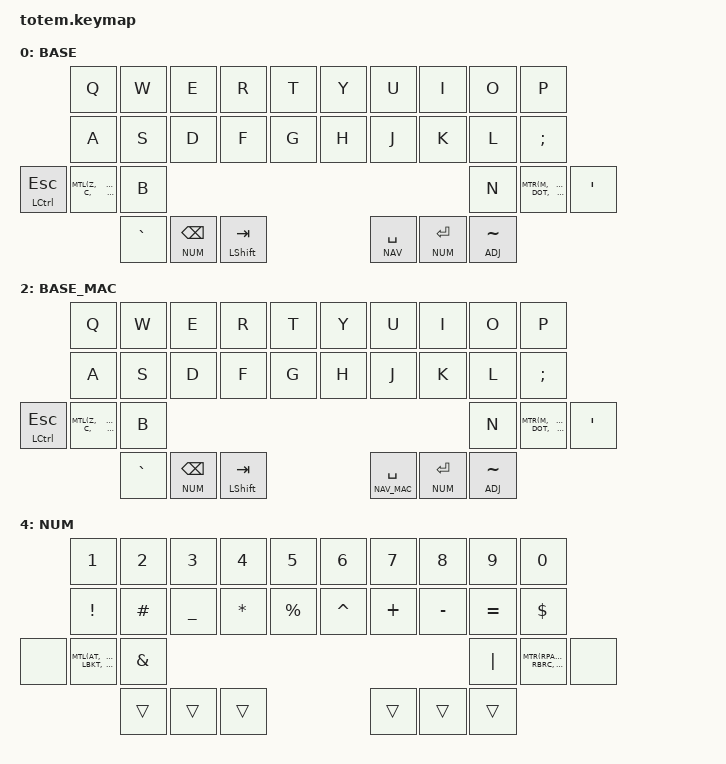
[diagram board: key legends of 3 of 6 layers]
//
//                                                        ▀▀▀▀▀     ▀▀▀▀▀          ▀▀█▀▀
//                                                        ▄▀▀▀▄  ▄  ▄▀▀▀▄  ▄  ▄▀▀▀▄  █  ▄▀▀▀▄
//                                                        █   █  █  █   █  █  █   █  █  █   █
//                                                         ▀▀▀   █   ▀▀▀   █   ▀▀▀   ▀   ▀▀▀
//                                                               █      ▄▄▄█▄▄▄    █   █  
//                                                               ▀      █  █  █     █▄█
//                                                             ▀▀▀▀▀    █  █  █      ▀
//                                                                      ▀  ▀  ▀
//
// ▄▄▄▄▄▄▄▄▄▄▄▄▄▄▄▄▄▄▄▄▄▄▄▄▄▄▄▄▄▄▄▄▄▄▄▄▄▄▄▄▄▄▄▄▄▄▄▄▄▄▄▄▄▄▄▄▄▄▄▄▄▄▄▄▄▄▄▄▄▄▄▄▄▄▄▄▄▄▄▄▄▄▄▄▄▄▄▄▄▄▄▄▄▄▄▄▄▄▄▄▄▄▄▄▄▄▄▄▄▄▄▄▄▄▄▄▄▄▄▄▄▄▄▄▄▄▄▄▄▄▄▄▄▄▄▄▄▄▄▄▄▄▄▄▄▄▄▄▄
       

#include <behaviors.dtsi>
#include <dt-bindings/zmk/keys.h>
#include <dt-bindings/zmk/bt.h>
#include <dt-bindings/zmk/outputs.h>

#define MTL(k1, k2, k3, k4) &mtl LGUI k1 &mtl LALT k2 &mtl LSHFT k3 &mtl LCTRL k4
#define MTR(k1, k2, k3, k4) &mtr RCTRL k1 &mtr RSHFT k2 &mtr RALT k3 &mtr RGUI k4

#define BASE      0
#define NAV       1
#define BASE_MAC  2
#define NAV_MAC   3
#define NUM       4
#define ADJ       5


// |------------------------|------------------------|
// | LEFT_HAND_KEYS         |        RIGHT_HAND_KEYS |
// |                        |                        |
// |     0  1  2  3  4      |       5  6  7  8  9    |
// |    10 11 12 13 14      |      15 16 17 18 19    |
// | 20 21 22 23 24 25      |      26 27 28 29 30 31 |
// |          32 33 34      |      35 36 37          |
// |------------------------|------------------------| 

/ {
    combos {
        compatible = "zmk,combos";
        combo_esc {
            timeout-ms = <35>;
            key-positions = <16 17>;
            bindings = <&kp ESC>;
        };
    };

    behaviors {
        mtt: mod_tap_thumbs {
            compatible = "zmk,behavior-hold-tap";
            #binding-cells = <2>;
            flavor = "balanced";
            tapping-term-ms = <180>;
            bindings = <&kp>, <&kp>;
            retro-tap;
            
        };
        mtl: mod_tap_left {
            compatible = "zmk,behavior-hold-tap";
            #binding-cells = <2>;
            flavor = "balanced";
            require-prior-idle-ms = <110>;
            tapping-term-ms = <215>;
            quick-tap-ms = <175>;
            bindings = <&kp>, <&kp>;
            hold-trigger-key-positions = <5 6 7 8 9 15 16 17 18 19 26 27 28 29 30 31 32 33 34 35 36 37>;
            hold-trigger-on-release;
        };
        mtr: mod_tap_right {
            compatible = "zmk,behavior-hold-tap";
            #binding-cells = <2>;
            flavor = "balanced";
            require-prior-idle-ms = <110>;
            tapping-term-ms = <215>;
            quick-tap-ms = <175>;
            bindings = <&kp>, <&kp>;
            hold-trigger-key-positions = <0 1 2 3 4 10 11 12 13 14 20 21 22 23 24 25 32 33 34 35 36 37>;
            hold-trigger-on-release;
        };
    };

    keymap {
            compatible = "zmk,keymap";
// ▄▄▄▄▄▄▄▄▄▄▄▄▄▄▄▄▄▄▄▄▄▄▄▄▄▄▄▄▄▄▄▄▄▄▄▄▄▄▄▄▄▄▄▄▄▄▄▄▄▄▄▄▄▄▄▄▄▄▄▄▄▄▄▄▄▄▄▄▄▄▄▄▄▄▄▄▄▄▄▄▄▄▄▄▄▄▄▄▄▄▄▄▄▄▄▄▄▄▄▄▄▄▄▄▄▄▄▄▄▄▄▄▄▄▄▄▄▄▄▄▄▄▄▄▄▄▄▄▄▄▄▄▄▄▄▄▄▄▄▄▄▄▄▄▄▄▄▄▄

                base_layer {
// ┏━━━━━━━━━━━━━━━━━━━━━━━━━━━━━━━━━━━━━━━┓
label= "BASE"                              ;
// ┗━━━━━━━━━━━━━━━━━━━━━━━━━━━━━━━━━━━━━━━┛
//             ┏━━━━━━━━━━━┳━━━━━━━━━━━┳━━━━━━━━━━━┳━━━━━━━━━━━┳━━━━━━━━━━━┓   ┏━━━━━━━━━━━┳━━━━━━━━━━━┳━━━━━━━━━━━┳━━━━━━━━━━━┳━━━━━━━━━━━┓
//             ┃     Q     ┃     W     ┃     E     ┃     R     ┃     T     ┃   ┃     Y     ┃     U     ┃     I     ┃     O     ┃     P     ┃
//             ┣━━━━━━━━━━━╋━━━━━━━━━━━╋━━━━━━━━━━━╋━━━━━━━━━━━╋━━━━━━━━━━━┫   ┣━━━━━━━━━━━╋━━━━━━━━━━━╋━━━━━━━━━━━╋━━━━━━━━━━━╋━━━━━━━━━━━┫
//             ┃     A     ┃     S     ┃     D     ┃     F     ┃     G     ┃   ┃     H     ┃     J     ┃     K     ┃     L     ┃     ;     ┃
// ┏━━━━━━━━━━━╋━━━━━━━━━━━╋━━━━━━━━━━━╋━━━━━━━━━━━╋━━━━━━━━━━━╋━━━━━━━━━━━┫   ┣━━━━━━━━━━━╋━━━━━━━━━━━╋━━━━━━━━━━━╋━━━━━━━━━━━╋━━━━━━━━━━━╋━━━━━━━━━━━┓
// ┃    ESC    ┃     Z     ┃     X     ┃     C     ┃     V     ┃     B     ┃   ┃     N     ┃     M     ┃     ,     ┃     .     ┃     /     ┃     '     ┃
// ┗━━━━━━━━━━━┻━━━━━━━━━━━┻━━━━━━━━━━━╋━━━━━━━━━━━╋━━━━━━━━━━━╋━━━━━━━━━━━┫   ┣━━━━━━━━━━━╋━━━━━━━━━━━╋━━━━━━━━━━━╋━━━━━━━━━━━┻━━━━━━━━━━━┻━━━━━━━━━━━┛
//                                     ┃           ┃    BSPC   ┃    TAB    ┃   ┃   SPACE   ┃   ENTER   ┃    ADJ    ┃
//                                     ┗━━━━━━━━━━━┻━━━━━━━━━━━┻━━━━━━━━━━━┛   ┗━━━━━━━━━━━┻━━━━━━━━━━━┻━━━━━━━━━━━┛
 bindings = <
// ╷           ╷           ╷           ╷           ╷           ╷           ╷   ╷           ╷           ╷           ╷           ╷           ╷           ╷

                &kp Q       &kp W       &kp E       &kp R       &kp T           &kp Y       &kp U       &kp I       &kp O       &kp P
                &kp A       &kp S       &kp D       &kp F       &kp G           &kp H       &kp J       &kp K       &kp L       &kp SEMI
 &mtt LCTRL ESC MTL(Z,          X,          C,          V)      &kp B           &kp N       MTR(M,          COMMA,      DOT,        FSLH)    &kp SQT
                            &kp GRAVE   &lt NUM BSPC &mtt LSHFT TAB             &lt NAV SPACE   &lt NUM ENTER   &lt ADJ TILDE
                        >;
                };

// ▄▄▄▄▄▄▄▄▄▄▄▄▄▄▄▄▄▄▄▄▄▄▄▄▄▄▄▄▄▄▄▄▄▄▄▄▄▄▄▄▄▄▄▄▄▄▄▄▄▄▄▄▄▄▄▄▄▄▄▄▄▄▄▄▄▄▄▄▄▄▄▄▄▄▄▄▄▄▄▄▄▄▄▄▄▄▄▄▄▄▄▄▄▄▄▄▄▄▄▄▄▄▄▄▄▄▄▄▄▄▄▄▄▄▄▄▄▄▄▄▄▄▄▄▄▄▄▄▄▄▄▄▄▄▄▄▄▄▄▄▄▄▄▄▄▄▄▄▄


                nav_layer {
// ┏━━━━━━━━━━━━━━━━━━━━━━━━━━━━━━━━━━━━━━━┓
label= "NAVI"                              ;
// ┗━━━━━━━━━━━━━━━━━━━━━━━━━━━━━━━━━━━━━━━┛
//             ┏━━━━━━━━━━━┳━━━━━━━━━━━┳━━━━━━━━━━━┳━━━━━━━━━━━┳━━━━━━━━━━━┓   ┏━━━━━━━━━━━┳━━━━━━━━━━━┳━━━━━━━━━━━┳━━━━━━━━━━━┳━━━━━━━━━━━┓
//             ┃           ┃           ┃CTRL(RIGHT)┃           ┃           ┃   ┃ CTRL(INS) ┃   PG_UP   ┃    HOME   ┃           ┃  SFT(INS) ┃
//             ┣━━━━━━━━━━━╋━━━━━━━━━━━╋━━━━━━━━━━━╋━━━━━━━━━━━╋━━━━━━━━━━━┫   ┣━━━━━━━━━━━╋━━━━━━━━━━━╋━━━━━━━━━━━╋━━━━━━━━━━━╋━━━━━━━━━━━┫
//             ┃    END    ┃    SS     ┃   PG_DN   ┃           ┃           ┃   ┃   LEFT    ┃    DOWN   ┃     UP    ┃   RIGHT   ┃    DEL    ┃
// ┏━━━━━━━━━━━╋━━━━━━━━━━━╋━━━━━━━━━━━╋━━━━━━━━━━━╋━━━━━━━━━━━╋━━━━━━━━━━━┫   ┣━━━━━━━━━━━╋━━━━━━━━━━━╋━━━━━━━━━━━╋━━━━━━━━━━━╋━━━━━━━━━━━╋━━━━━━━━━━━┓
// ┃   CAPS    ┃   K_PP    ┃   K_PREV  ┃  K_NEXT   ┃           ┃ CTRL(LEFT)┃   ┃           ┃           ┃           ┃           ┃           ┃           ┃
// ┗━━━━━━━━━━━┻━━━━━━━━━━━┻━━━━━━━━━━━╋━━━━━━━━━━━╋━━━━━━━━━━━╋━━━━━━━━━━━┫   ┣━━━━━━━━━━━╋━━━━━━━━━━━╋━━━━━━━━━━━╋━━━━━━━━━━━┻━━━━━━━━━━━┻━━━━━━━━━━━┛
//                                     ┃           ┃           ┃           ┃   ┃           ┃           ┃           ┃
//                                     ┗━━━━━━━━━━━┻━━━━━━━━━━━┻━━━━━━━━━━━┛   ┗━━━━━━━━━━━┻━━━━━━━━━━━┻━━━━━━━━━━━┛
 bindings = <
// ╷           ╷           ╷           ╷           ╷           ╷           ╷   ╷           ╷           ╷           ╷           ╷           ╷           ╷

                &none       &none     &kp LC(RIGHT) &none       &none           &kp LC(INS) &kp PG_UP   &kp HOME    &none       &kp LS(INS)
                &kp END  &kp LA(LS(S))  &kp PG_DN   &none       &none           &kp LEFT    &kp DOWN    &kp UP      &kp RIGHT   &kp DEL
    &kp CAPS    MTL(K_PP,   K_PREV,     K_NEXT,     GRAVE)      &kp LC(LEFT)    &none       &sk RCTRL   &sk RSHFT   &sk RALT    &sk RGUI   &none      
                                        &trans      &trans      &trans          &trans      &trans      &trans      
                        >;
                };

// // ▄▄▄▄▄▄▄▄▄▄▄▄▄▄▄▄▄▄▄▄▄▄▄▄▄▄▄▄▄▄▄▄▄▄▄▄▄▄▄▄▄▄▄▄▄▄▄▄▄▄▄▄▄▄▄▄▄▄▄▄▄▄▄▄▄▄▄▄▄▄▄▄▄▄▄▄▄▄▄▄▄▄▄▄▄▄▄▄▄▄▄▄▄▄▄▄▄▄▄▄▄▄▄▄▄▄▄▄▄▄▄▄▄▄▄▄▄▄▄▄▄▄▄▄▄▄▄▄▄▄▄▄▄▄▄▄▄▄▄▄▄▄▄▄▄▄▄▄▄


                base_mac_layer {
// ┏━━━━━━━━━━━━━━━━━━━━━━━━━━━━━━━━━━━━━━━┓
label= "BASE_MAC"                          ;
// ┗━━━━━━━━━━━━━━━━━━━━━━━━━━━━━━━━━━━━━━━┛
//             ┏━━━━━━━━━━━┳━━━━━━━━━━━┳━━━━━━━━━━━┳━━━━━━━━━━━┳━━━━━━━━━━━┓   ┏━━━━━━━━━━━┳━━━━━━━━━━━┳━━━━━━━━━━━┳━━━━━━━━━━━┳━━━━━━━━━━━┓
//             ┃     Q     ┃     W     ┃     E     ┃     R     ┃     T     ┃   ┃     Y     ┃     U     ┃     I     ┃     O     ┃     P     ┃
//             ┣━━━━━━━━━━━╋━━━━━━━━━━━╋━━━━━━━━━━━╋━━━━━━━━━━━╋━━━━━━━━━━━┫   ┣━━━━━━━━━━━╋━━━━━━━━━━━╋━━━━━━━━━━━╋━━━━━━━━━━━╋━━━━━━━━━━━┫
//             ┃     A     ┃     S     ┃     D     ┃     F     ┃     G     ┃   ┃     H     ┃     J     ┃     K     ┃     L     ┃     ;     ┃
// ┏━━━━━━━━━━━╋━━━━━━━━━━━╋━━━━━━━━━━━╋━━━━━━━━━━━╋━━━━━━━━━━━╋━━━━━━━━━━━┫   ┣━━━━━━━━━━━╋━━━━━━━━━━━╋━━━━━━━━━━━╋━━━━━━━━━━━╋━━━━━━━━━━━╋━━━━━━━━━━━┓
// ┃    ESC    ┃     Z     ┃     X     ┃     C     ┃     V     ┃     B     ┃   ┃     N     ┃     M     ┃     ,     ┃     .     ┃     /     ┃     '     ┃
// ┗━━━━━━━━━━━┻━━━━━━━━━━━┻━━━━━━━━━━━╋━━━━━━━━━━━╋━━━━━━━━━━━╋━━━━━━━━━━━┫   ┣━━━━━━━━━━━╋━━━━━━━━━━━╋━━━━━━━━━━━╋━━━━━━━━━━━┻━━━━━━━━━━━┻━━━━━━━━━━━┛
//                                     ┃           ┃    BSPC   ┃    TAB    ┃   ┃   SPACE   ┃   ENTER   ┃    ADJ    ┃
//                                     ┗━━━━━━━━━━━┻━━━━━━━━━━━┻━━━━━━━━━━━┛   ┗━━━━━━━━━━━┻━━━━━━━━━━━┻━━━━━━━━━━━┛
 bindings = <
// ╷           ╷           ╷           ╷           ╷           ╷           ╷   ╷           ╷           ╷           ╷           ╷           ╷           ╷

                &kp Q       &kp W       &kp E       &kp R       &kp T           &kp Y       &kp U       &kp I       &kp O       &kp P
                &kp A       &kp S       &kp D       &kp F       &kp G           &kp H       &kp J       &kp K       &kp L       &kp SEMI
 &mtt LCTRL ESC MTL(Z,          X,          C,          V)      &kp B           &kp N       MTR(M,          COMMA,      DOT,        FSLH)    &kp SQT
                            &kp GRAVE   &lt NUM BSPC &mtt LSHFT TAB             &lt NAV_MAC SPACE   &lt NUM ENTER   &lt ADJ TILDE
                        >;
                };

// ▄▄▄▄▄▄▄▄▄▄▄▄▄▄▄▄▄▄▄▄▄▄▄▄▄▄▄▄▄▄▄▄▄▄▄▄▄▄▄▄▄▄▄▄▄▄▄▄▄▄▄▄▄▄▄▄▄▄▄▄▄▄▄▄▄▄▄▄▄▄▄▄▄▄▄▄▄▄▄▄▄▄▄▄▄▄▄▄▄▄▄▄▄▄▄▄▄▄▄▄▄▄▄▄▄▄▄▄▄▄▄▄▄▄▄▄▄▄▄▄▄▄▄▄▄▄▄▄▄▄▄▄▄▄▄▄▄▄▄▄▄▄▄▄▄▄▄▄▄


                nav_mac_layer {
// ┏━━━━━━━━━━━━━━━━━━━━━━━━━━━━━━━━━━━━━━━┓
label= "NAVI_MAC"                          ;
// ┗━━━━━━━━━━━━━━━━━━━━━━━━━━━━━━━━━━━━━━━┛
//             ┏━━━━━━━━━━━┳━━━━━━━━━━━┳━━━━━━━━━━━┳━━━━━━━━━━━┳━━━━━━━━━━━┓   ┏━━━━━━━━━━━┳━━━━━━━━━━━┳━━━━━━━━━━━┳━━━━━━━━━━━┳━━━━━━━━━━━┓
//             ┃           ┃           ┃ ALT(RIGHT)┃           ┃           ┃   ┃ CTRL(INS) ┃   PG_UP   ┃ GUI(LEFT) ┃           ┃  SFT(INS) ┃
//             ┣━━━━━━━━━━━╋━━━━━━━━━━━╋━━━━━━━━━━━╋━━━━━━━━━━━╋━━━━━━━━━━━┫   ┣━━━━━━━━━━━╋━━━━━━━━━━━╋━━━━━━━━━━━╋━━━━━━━━━━━╋━━━━━━━━━━━┫
//             ┃GUI(RIGHT) ┃    SS     ┃   PG_DN   ┃           ┃           ┃   ┃   LEFT    ┃    DOWN   ┃     UP    ┃   RIGHT   ┃    DEL    ┃
// ┏━━━━━━━━━━━╋━━━━━━━━━━━╋━━━━━━━━━━━╋━━━━━━━━━━━╋━━━━━━━━━━━╋━━━━━━━━━━━┫   ┣━━━━━━━━━━━╋━━━━━━━━━━━╋━━━━━━━━━━━╋━━━━━━━━━━━╋━━━━━━━━━━━╋━━━━━━━━━━━┓
// ┃   CAPS    ┃   K_PP    ┃   K_PREV  ┃  K_NEXT   ┃           ┃ ALT(LEFT) ┃   ┃           ┃           ┃           ┃           ┃           ┃           ┃
// ┗━━━━━━━━━━━┻━━━━━━━━━━━┻━━━━━━━━━━━╋━━━━━━━━━━━╋━━━━━━━━━━━╋━━━━━━━━━━━┫   ┣━━━━━━━━━━━╋━━━━━━━━━━━╋━━━━━━━━━━━╋━━━━━━━━━━━┻━━━━━━━━━━━┻━━━━━━━━━━━┛
//                                     ┃           ┃           ┃           ┃   ┃           ┃           ┃           ┃
//                                     ┗━━━━━━━━━━━┻━━━━━━━━━━━┻━━━━━━━━━━━┛   ┗━━━━━━━━━━━┻━━━━━━━━━━━┻━━━━━━━━━━━┛
 bindings = <
// ╷           ╷           ╷           ╷           ╷           ╷           ╷   ╷           ╷           ╷           ╷           ╷           ╷           ╷

                &none       &none   &kp LA(RIGHT)   &none       &none           &kp LC(INS) &kp PG_UP  &kp LG(LEFT) &none       &kp LS(INS)
        &kp LG(RIGHT) &kp LG(LC(DOLLAR)) &kp PG_DN  &none       &none           &kp LEFT    &kp DOWN    &kp UP      &kp RIGHT   &kp DEL
    &kp CAPS    MTL(C_PP,   C_PREV,     C_NEXT,     GRAVE)      &kp LA(LEFT)    &none       &sk RCTRL   &sk RSHFT   &sk RALT    &sk RGUI   &none      
                                        &trans      &trans      &trans          &trans      &trans      &trans      
                        >;
                };

// ▄▄▄▄▄▄▄▄▄▄▄▄▄▄▄▄▄▄▄▄▄▄▄▄▄▄▄▄▄▄▄▄▄▄▄▄▄▄▄▄▄▄▄▄▄▄▄▄▄▄▄▄▄▄▄▄▄▄▄▄▄▄▄▄▄▄▄▄▄▄▄▄▄▄▄▄▄▄▄▄▄▄▄▄▄▄▄▄▄▄▄▄▄▄▄▄▄▄▄▄▄▄▄▄▄▄▄▄▄▄▄▄▄▄▄▄▄▄▄▄▄▄▄▄▄▄▄▄▄▄▄▄▄▄▄▄▄▄▄▄▄▄▄▄▄▄▄▄▄



                num_layer {
// ┏━━━━━━━━━━━━━━━━━━━━━━━━━━━━━━━━━━━━━━━┓
label= "NUM"                               ;
// ┗━━━━━━━━━━━━━━━━━━━━━━━━━━━━━━━━━━━━━━━┛
//             ┏━━━━━━━━━━━┳━━━━━━━━━━━┳━━━━━━━━━━━┳━━━━━━━━━━━┳━━━━━━━━━━━┓   ┏━━━━━━━━━━━┳━━━━━━━━━━━┳━━━━━━━━━━━┳━━━━━━━━━━━┳━━━━━━━━━━━┓
//             ┃     1     ┃     2     ┃     3     ┃     4     ┃     5     ┃   ┃     6     ┃     7     ┃     8     ┃     9     ┃     0     ┃
//             ┣━━━━━━━━━━━╋━━━━━━━━━━━╋━━━━━━━━━━━╋━━━━━━━━━━━╋━━━━━━━━━━━┫   ┣━━━━━━━━━━━╋━━━━━━━━━━━╋━━━━━━━━━━━╋━━━━━━━━━━━╋━━━━━━━━━━━┫
//             ┃     !     ┃     #     ┃     _     ┃     *     ┃     %     ┃   ┃     ^     ┃     +     ┃     -     ┃     =     ┃     $     ┃
// ┏━━━━━━━━━━━╋━━━━━━━━━━━╋━━━━━━━━━━━╋━━━━━━━━━━━╋━━━━━━━━━━━╋━━━━━━━━━━━┫   ┣━━━━━━━━━━━╋━━━━━━━━━━━╋━━━━━━━━━━━╋━━━━━━━━━━━╋━━━━━━━━━━━╋━━━━━━━━━━━┓
// ┃           ┃     @     ┃     {     ┃     [     ┃     (     ┃     &     ┃   ┃     |     ┃     )     ┃     ]     ┃     }     ┃     \     ┃           ┃
// ┗━━━━━━━━━━━┻━━━━━━━━━━━┻━━━━━━━━━━━╋━━━━━━━━━━━╋━━━━━━━━━━━╋━━━━━━━━━━━┫   ┣━━━━━━━━━━━╋━━━━━━━━━━━╋━━━━━━━━━━━╋━━━━━━━━━━━┻━━━━━━━━━━━┻━━━━━━━━━━━┛
//                                     ┃           ┃           ┃           ┃   ┃           ┃           ┃           ┃
//                                     ┗━━━━━━━━━━━┻━━━━━━━━━━━┻━━━━━━━━━━━┛   ┗━━━━━━━━━━━┻━━━━━━━━━━━┻━━━━━━━━━━━┛
 bindings = <
// ╷           ╷           ╷           ╷           ╷           ╷           ╷   ╷           ╷           ╷           ╷           ╷           ╷           ╷

                &kp N1      &kp N2      &kp N3      &kp N4      &kp N5          &kp N6      &kp N7      &kp N8      &kp N9      &kp N0
                &kp EXCL    &kp HASH    &kp UNDER   &kp ASTRK   &kp PRCNT       &kp CARET   &kp PLUS    &kp MINUS   &kp EQUAL   &kp DLLR
    &none       MTL(AT,         LBRC,       LBKT,       LPAR)   &kp AMPS        &kp PIPE    MTR(RPAR,       RBKT,       RBRC,       BSLH)    &none        
                                        &trans      &trans      &trans          &trans      &trans      &trans    
                        >;
                };

// ▄▄▄▄▄▄▄▄▄▄▄▄▄▄▄▄▄▄▄▄▄▄▄▄▄▄▄▄▄▄▄▄▄▄▄▄▄▄▄▄▄▄▄▄▄▄▄▄▄▄▄▄▄▄▄▄▄▄▄▄▄▄▄▄▄▄▄▄▄▄▄▄▄▄▄▄▄▄▄▄▄▄▄▄▄▄▄▄▄▄▄▄▄▄▄▄▄▄▄▄▄▄▄▄▄▄▄▄▄▄▄▄▄▄▄▄▄▄▄▄▄▄▄▄▄▄▄▄▄▄▄▄▄▄▄▄▄▄▄▄▄▄▄▄▄▄▄▄▄


                adj_layer {
// ┏━━━━━━━━━━━━━━━━━━━━━━━━━━━━━━━━━━━━━━━┓
label= "ADJ"                               ;
// ┗━━━━━━━━━━━━━━━━━━━━━━━━━━━━━━━━━━━━━━━┛
//             ┏━━━━━━━━━━━┳━━━━━━━━━━━┳━━━━━━━━━━━┳━━━━━━━━━━━┳━━━━━━━━━━━┓   ┏━━━━━━━━━━━┳━━━━━━━━━━━┳━━━━━━━━━━━┳━━━━━━━━━━━┳━━━━━━━━━━━┓
//             ┃           ┃           ┃           ┃           ┃           ┃   ┃           ┃    F7     ┃    F8     ┃    F9     ┃    F12    ┃
//             ┣━━━━━━━━━━━╋━━━━━━━━━━━╋━━━━━━━━━━━╋━━━━━━━━━━━╋━━━━━━━━━━━┫   ┣━━━━━━━━━━━╋━━━━━━━━━━━╋━━━━━━━━━━━╋━━━━━━━━━━━╋━━━━━━━━━━━┫
//             ┃ BT CLR    ┃    BT2    ┃    BT1    ┃    BT0    ┃           ┃   ┃           ┃    F4     ┃    F5     ┃    F6     ┃    F11    ┃
// ┏━━━━━━━━━━━╋━━━━━━━━━━━╋━━━━━━━━━━━╋━━━━━━━━━━━╋━━━━━━━━━━━╋━━━━━━━━━━━┫   ┣━━━━━━━━━━━╋━━━━━━━━━━━╋━━━━━━━━━━━╋━━━━━━━━━━━╋━━━━━━━━━━━╋━━━━━━━━━━━┓
// ┃   MAC     ┃           ┃           ┃           ┃           ┃           ┃   ┃           ┃    F1     ┃    F2     ┃    F3     ┃    F10    ┃           ┃
// ┗━━━━━━━━━━━┻━━━━━━━━━━━┻━━━━━━━━━━━╋━━━━━━━━━━━╋━━━━━━━━━━━╋━━━━━━━━━━━┫   ┣━━━━━━━━━━━╋━━━━━━━━━━━╋━━━━━━━━━━━╋━━━━━━━━━━━┻━━━━━━━━━━━┻━━━━━━━━━━━┛
//                                     ┃           ┃           ┃           ┃   ┃           ┃           ┃           ┃
//                                     ┗━━━━━━━━━━━┻━━━━━━━━━━━┻━━━━━━━━━━━┛   ┗━━━━━━━━━━━┻━━━━━━━━━━━┻━━━━━━━━━━━┛
 bindings = <
// ╷           ╷           ╷           ╷           ╷           ╷           ╷   ╷           ╷           ╷           ╷           ╷           ╷           ╷
                &trans      &trans      &trans      &trans      &trans          &trans      &kp F7      &kp F8      &kp F9      &kp F12
                &bt BT_CLR  &bt BT_SEL 2 &bt BT_SEL 1 &bt BT_SEL 0 &trans       &trans      &kp F4      &kp F5      &kp F6      &kp F11  
    &trans      &trans      &trans      &trans      &tog 2      &trans          &trans      &kp F1      &kp F2      &kp F3      &kp F10     &trans         
                                        &trans      &trans      &trans          &trans      &trans      &trans      
                        >;
                };

        };
};
